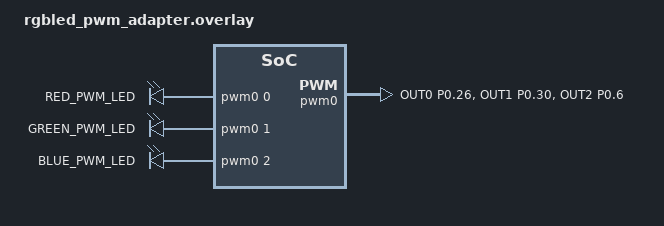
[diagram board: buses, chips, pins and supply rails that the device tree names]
#include <dt-bindings/pwm/pwm.h>
#include <dt-bindings/pinctrl/nrf-pinctrl.h>

/ {
    aliases {
        led-red-pwm = &red_pwm_led;
        led-green-pwm = &green_pwm_led;
        led-blue-pwm = &blue_pwm_led;
    };

    pwmleds {
        compatible = "pwm-leds";

        red_pwm_led: red_pwm_led {
            pwms = <&pwm0 0 PWM_MSEC(1) PWM_POLARITY_INVERTED>;
            label = "RED_PWM_LED";
        };

        green_pwm_led: green_pwm_led {
            pwms = <&pwm0 1 PWM_MSEC(1) PWM_POLARITY_INVERTED>;
            label = "GREEN_PWM_LED";
        };

        blue_pwm_led: blue_pwm_led {
            pwms = <&pwm0 2 PWM_MSEC(1) PWM_POLARITY_INVERTED>;
            label = "BLUE_PWM_LED";
        };
    };
};

&pwm0 {
    status = "okay";
    pinctrl-0 = <&pwm0_default>;
    pinctrl-1 = <&pwm0_sleep>;
    pinctrl-names = "default", "sleep";
};

&pinctrl {
    pwm0_default: pwm0_default {
        group1 {
            psels = <
                NRF_PSEL(PWM_OUT0, 0, 26)
                NRF_PSEL(PWM_OUT1, 0, 30)
                NRF_PSEL(PWM_OUT2, 0, 6)
            >;
        };
    };

    pwm0_sleep: pwm0_sleep {
        group1 {
            psels = <
                NRF_PSEL(PWM_OUT0, 0, 26)
                NRF_PSEL(PWM_OUT1, 0, 30)
                NRF_PSEL(PWM_OUT2, 0, 6)
            >;
            low-power-enable;
        };
    };
};
